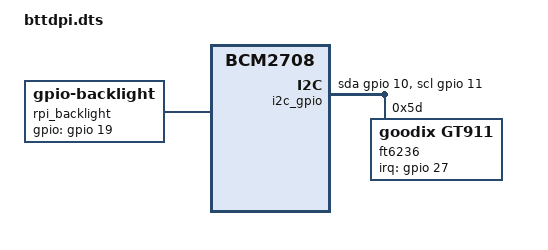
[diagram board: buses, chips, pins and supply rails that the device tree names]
/dts-v1/;
/plugin/;
/ {
    compatible = "brcm,bcm2835,bcm2708";
    fragment@0 {
        target = <&fb>;
        __overlay__ {
            pinctrl-names = "default";
            pinctrl-0 = <0x1>;
        };
    };
    fragment@1 {
        target = <&gpio>;
        __overlay__ {
            dpi18_pins: dpi18_pins {
                brcm,pins = <0 1 2 3 4 5 6 7 8 9 12 13 14 15 16 17 20 21 22 23 24 25>;
                brcm,function = <0x6>;
                brcm,pull = <0x0>;
                phandle = <0x1>;
            };
        };
    };
    fragment@2 {
        target-path = "/";
        __overlay__ {
            rpi_backlight: rpi_backlight {
                compatible = "gpio-backlight";
                gpios = <&gpio 19 0>;
                default-on;
                pinctrl-names = "default";
                pinctrl-0 = <&dpi18_pins>;
            };
        };
    };
    fragment@3 {
        target-path = "/";
        __overlay__ {
            i2c_gpio: i2c@11 {
                compatible = "i2c-gpio";
                gpios = <&gpio 10 0 /* sda */
                     &gpio 11 0 /* scl */
                    >;
                i2c-gpio,delay-us = <4>;        /* ~100 kHz */
                #address-cells = <1>;
                #size-cells = <0>;
            };
        };
    };
    fragment@4 {
        target = <&i2c_gpio>;
        __overlay__ {
            /* needed to avoid dtc warning */
            #address-cells = <1>;
            #size-cells = <0>;
            ft6236: ft6236@5d {
                compatible = "goodix,gt911";
                reg = <0x5d>;
                interrupt-parent = <&gpio>;
                interrupts = <27 2>;
                touchscreen-size-x = <800>;
                touchscreen-size-y = <480>;
            };
        };
    };
    __symbols__ {
        dpi18_pins = "/fragment@1/__overlay__/dpi18_pins";
    };
    __local_fixups__ {
        fragment@0 {
            __overlay__ {
                pinctrl-0 = <0x0>;
            };
        };
    };
    __overrides__ {
    };
};
